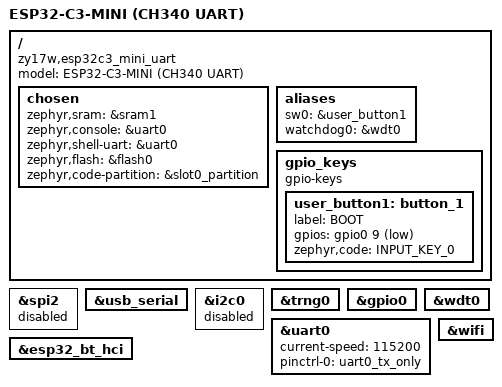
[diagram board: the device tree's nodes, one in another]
/*
 * Copyright (c) 2025 Arrel Neumiller
 * SPDX-License-Identifier: Apache-2.0
 *
 * ESP32-C3-MINI (CH340 UART) — UART0 console via CH340, no LED strip.
 * GPIO20 = CH340 RX, GPIO21 = CH340 TX.
 */

/dts-v1/;

#include <espressif/esp32c3/esp32c3_fx4.dtsi>
#include "esp32c3_mini-pinctrl.dtsi"
#include <zephyr/dt-bindings/input/input-event-codes.h>
#include <espressif/partitions_0x0_default.dtsi>

/ {
	model = "ESP32-C3-MINI (CH340 UART)";
	compatible = "zy17w,esp32c3_mini_uart";

	chosen {
		zephyr,sram = &sram1;
		zephyr,console = &uart0;
		zephyr,shell-uart = &uart0;
		zephyr,flash = &flash0;
		zephyr,code-partition = &slot0_partition;
	};

	aliases {
		sw0 = &user_button1;
		watchdog0 = &wdt0;
	};

	gpio_keys {
		compatible = "gpio-keys";

		user_button1: button_1 {
			label = "BOOT";
			gpios = <&gpio0 9 (GPIO_PULL_UP | GPIO_ACTIVE_LOW)>;
			zephyr,code = <INPUT_KEY_0>;
		};
	};
};

&spi2 {
	status = "disabled";
};

&usb_serial {
	status = "okay";
};

&i2c0 {
	status = "disabled";
};

&trng0 {
	status = "okay";
};

&gpio0 {
	status = "okay";
};

&wdt0 {
	status = "okay";
};

&uart0 {
	status = "okay";
	current-speed = <115200>;
	pinctrl-0 = <&uart0_tx_only>;
	pinctrl-names = "default";
};

&esp32_bt_hci {
	status = "okay";
};

&wifi {
	status = "okay";
};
